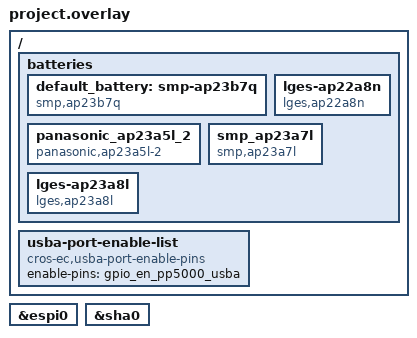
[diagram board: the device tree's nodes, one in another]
/* Copyright 2024 The ChromiumOS Authors
 * Use of this source code is governed by a BSD-style license that can be
 * found in the LICENSE file.
 */

/* fatcat program common DTS includes */

#include <cros/integrated_fwid.dtsi>

/* felino project DTS includes */
#include "gpios.dtsi"

#include "adc.dtsi"
#include "binman.dtsi"
#include "console.dtsi"
#include "fan.dtsi"
#include "i2c.dtsi"
#include "interrupts.dtsi"
#include "keyboard.dtsi"
#include "led_pins.dtsi"
#include "led_policy.dtsi"
#include "power_signals.dtsi"
#include "temp_sensors.dtsi"
#include "usb_typec.dtsi"

/ {
	batteries {
		default_battery: smp-ap23b7q {
			compatible = "smp,ap23b7q", "battery-smart";
		};
		panasonic_ap23a5l_2 {
			compatible = "panasonic,ap23a5l-2", "battery-smart";
		};
		lges-ap22a8n {
			compatible = "lges,ap22a8n", "battery-smart";
		};
		smp_ap23a7l {
			compatible = "smp,ap23a7l", "battery-smart";
		};
		lges-ap23a8l {
			compatible = "lges,ap23a8l", "battery-smart";
		};
	};

	usba-port-enable-list {
		compatible = "cros-ec,usba-port-enable-pins";
		enable-pins = <&gpio_en_pp5000_usba>;
	};
};

/* AP interface */
&espi0 {
	status = "okay";
};

&sha0 {
	status = "okay";
};
